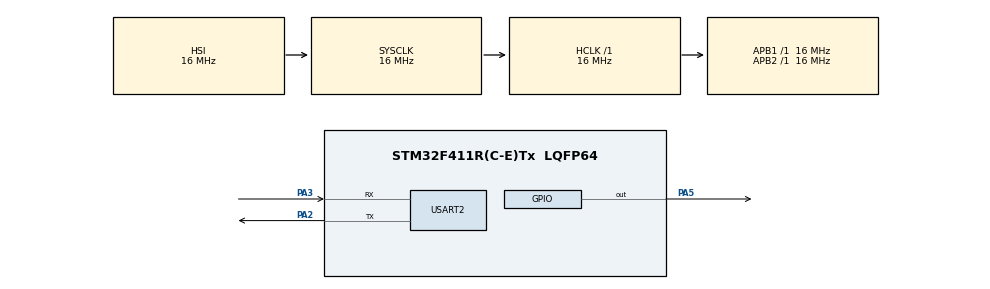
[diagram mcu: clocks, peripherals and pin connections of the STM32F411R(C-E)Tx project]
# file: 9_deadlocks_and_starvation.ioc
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FREERTOS.Tasks01=defaultTask,24,128,StartDefaultTask,Default,NULL,Dynamic,NULL,NULL
FREERTOS.configGENERATE_RUN_TIME_STATS=1
FREERTOS.configRECORD_STACK_HIGH_ADDRESS=1
FREERTOS.configUSE_NEWLIB_REENTRANT=1
FREERTOS.configUSE_STATS_FORMATTING_FUNCTIONS=1
Mcu.Family=STM32F4
Mcu.Name=STM32F411R(C-E)Tx
Mcu.Package=LQFP64
NVIC.PriorityGroup=NVIC_PRIORITYGROUP_4
NVIC.TIM1_TRG_COM_TIM11_IRQn=true\:15\:0\:false\:false\:true\:false\:false\:true\:true
NVIC.TimeBase=TIM1_TRG_COM_TIM11_IRQn
NVIC.TimeBaseIP=TIM11
PA2.Mode=Asynchronous
PA2.Signal=USART2_TX
PA3.Mode=Asynchronous
PA3.Signal=USART2_RX
PA5.Signal=GPIO_Output
PH0\ -\ OSC_IN.Mode=HSE-External-Oscillator
PH0\ -\ OSC_IN.Signal=RCC_OSC_IN
PH1\ -\ OSC_OUT.Mode=HSE-External-Oscillator
PH1\ -\ OSC_OUT.Signal=RCC_OSC_OUT
ProjectManager.HeapSize=0x200
ProjectManager.StackSize=0x400
ProjectManager.TargetToolchain=STM32CubeIDE
RCC.AHBFreq_Value=16000000
RCC.APB1Freq_Value=16000000
RCC.APB2Freq_Value=16000000
RCC.CortexFreq_Value=16000000
RCC.HSE_VALUE=25000000
RCC.HSI_VALUE=16000000
RCC.LSE_VALUE=32768
RCC.SYSCLKFreq_VALUE=16000000
RCC.VCOOutputFreq_Value=192000000
USART2.VirtualMode=VM_ASYNC
VP_FREERTOS_VS_CMSIS_V2.Mode=CMSIS_V2
VP_SYS_VS_tim11.Mode=TIM11
board=custom

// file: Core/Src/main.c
/* USER CODE BEGIN Header */
/**
 ******************************************************************************
 * @file           : main.c
 * @brief          : Main program body
 ******************************************************************************
 * @attention
 *
 * Copyright (c) 2026 STMicroelectronics.
 * All rights reserved.
 *
 * This software is licensed under terms that can be found in the LICENSE file
 * in the root directory of this software component.
 * If no LICENSE file comes with this software, it is provided AS-IS.
 *
 ******************************************************************************
 */
/* USER CODE END Header */
#include "main.h"
#include "cmsis_os.h"

/* USER CODE BEGIN Includes */

/* Standard library includes */
#include <stdio.h>
#include <stdlib.h>
#include <string.h>
#include <math.h>

/* FreeRTOS includes */
#include "timers.h"
#include "semphr.h"
#include "queue.h"

/* User includes */

/* USER CODE END Includes */

/* USER CODE BEGIN PD */
#define MAX(x, y) (((x) > (y)) ? (x) : (y))
#define MIN(x, y) (((x) < (y)) ? (x) : (y))

/* USER CODE END PD */

UART_HandleTypeDef huart2;

/* Definitions for defaultTask */
osThreadId_t defaultTaskHandle;
const osThreadAttr_t defaultTask_attributes = { .name = "defaultTask",
		.stack_size = 128 * 4, .priority = (osPriority_t) osPriorityNormal, };
/* USER CODE BEGIN PV */

/* ----------------------------- VARIABLES ---------------------------- */

//static const TickType_t task_delay = 20 / portTICK_PERIOD_MS;
/* Settings */
enum {
	NUM_TASKS = 5
};
// Number of tasks (philosophers)
enum {
	TASK_STACK_SIZE = 2048
};
// In bytes

// Globals
static char *task_names[NUM_TASKS];
static osThreadId_t *eatTaskHandles;
static osThreadAttr_t *eatTask_attributes;
/* flags */

/* Mutexes and Semaphores */
static SemaphoreHandle_t bin_sem; 		// Wait for parameters to be read
static SemaphoreHandle_t done_sem;  	// Notifies main task when done
static SemaphoreHandle_t chopstick[NUM_TASKS];

static SemaphoreHandle_t print_mutex;   // Serialize UART output

/* Queues and related structs */

/* ------------------------------ TASKS ------------------------------ */

osThreadId_t calcTaskHandle;
const osThreadAttr_t calcTask_attributes = { .name = "calcTask", .stack_size =
		512 * 4, .priority = (osPriority_t) osPriorityNormal, };

/* ----------------------------- CALLBACKS ---------------------------- */

/* USER CODE END PV */

void SystemClock_Config(void);
static void MX_GPIO_Init(void);
static void MX_USART2_UART_Init(void);
void StartDefaultTask(void *argument);

/* USER CODE BEGIN PFP */

/* ------------------------ FUNCTION SIGNATURES ----------------------- */

/* USER CODE END PFP */

int main(void) {

	/* MCU Configuration--------------------------------------------------------*/

	/* Reset of all peripherals, Initializes the Flash interface and the Systick. */
	HAL_Init();

	/* Configure the system clock */
	SystemClock_Config();

	/* Initialize all configured peripherals */
	MX_GPIO_Init();
	MX_USART2_UART_Init();
	/* USER CODE BEGIN 2 */

	/* Create Mutexes and Semaphores */

	/* Disable internal buffering for stdin */
	setvbuf(stdin, NULL, _IONBF, 0);

	/* USER CODE END 2 */

	/* Init scheduler */
	osKernelInitialize();

	/* Create the thread(s) */
	/* creation of defaultTask */
	defaultTaskHandle = osThreadNew(StartDefaultTask, NULL,
			&defaultTask_attributes);

	printf("[::::::::::::::: RTOS KERNEL START :::::::::::::::]\r\n");

	/* Start scheduler */
	osKernelStart();

	/* We should never get here as control is now taken by the scheduler */

	/* Infinite loop */
	while (1) {

	}
}

void SystemClock_Config(void) {
	RCC_OscInitTypeDef RCC_OscInitStruct = { 0 };
	RCC_ClkInitTypeDef RCC_ClkInitStruct = { 0 };

	/** Configure the main internal regulator output voltage
	 */
	__HAL_RCC_PWR_CLK_ENABLE();
	__HAL_PWR_VOLTAGESCALING_CONFIG(PWR_REGULATOR_VOLTAGE_SCALE1);

	/** Initializes the RCC Oscillators according to the specified parameters
	 * in the RCC_OscInitTypeDef structure.
	 */
	RCC_OscInitStruct.OscillatorType = RCC_OSCILLATORTYPE_HSI;
	RCC_OscInitStruct.HSIState = RCC_HSI_ON;
	RCC_OscInitStruct.HSICalibrationValue = RCC_HSICALIBRATION_DEFAULT;
	RCC_OscInitStruct.PLL.PLLState = RCC_PLL_NONE;
	if (HAL_RCC_OscConfig(&RCC_OscInitStruct) != HAL_OK) {
		Error_Handler();
	}

	/** Initializes the CPU, AHB and APB buses clocks
	 */
	RCC_ClkInitStruct.ClockType = RCC_CLOCKTYPE_HCLK | RCC_CLOCKTYPE_SYSCLK
			| RCC_CLOCKTYPE_PCLK1 | RCC_CLOCKTYPE_PCLK2;
	RCC_ClkInitStruct.SYSCLKSource = RCC_SYSCLKSOURCE_HSI;
	RCC_ClkInitStruct.AHBCLKDivider = RCC_SYSCLK_DIV1;
	RCC_ClkInitStruct.APB1CLKDivider = RCC_HCLK_DIV1;
	RCC_ClkInitStruct.APB2CLKDivider = RCC_HCLK_DIV1;

	if (HAL_RCC_ClockConfig(&RCC_ClkInitStruct, FLASH_LATENCY_0) != HAL_OK) {
		Error_Handler();
	}
}

static void MX_USART2_UART_Init(void) {

	huart2.Instance = USART2;
	huart2.Init.BaudRate = 115200;
	huart2.Init.WordLength = UART_WORDLENGTH_8B;
	huart2.Init.StopBits = UART_STOPBITS_1;
	huart2.Init.Parity = UART_PARITY_NONE;
	huart2.Init.Mode = UART_MODE_TX_RX;
	huart2.Init.HwFlowCtl = UART_HWCONTROL_NONE;
	huart2.Init.OverSampling = UART_OVERSAMPLING_16;
	if (HAL_UART_Init(&huart2) != HAL_OK) {
		Error_Handler();
	}

}

static void MX_GPIO_Init(void) {
	GPIO_InitTypeDef GPIO_InitStruct = { 0 };

	/* GPIO Ports Clock Enable */
	__HAL_RCC_GPIOH_CLK_ENABLE();
	__HAL_RCC_GPIOA_CLK_ENABLE();

	/*Configure GPIO pin Output Level */
	HAL_GPIO_WritePin(GPIOA, GPIO_PIN_5, GPIO_PIN_RESET);

	/*Configure GPIO pin : PA5 */
	GPIO_InitStruct.Pin = GPIO_PIN_5;
	GPIO_InitStruct.Mode = GPIO_MODE_OUTPUT_PP;
	GPIO_InitStruct.Pull = GPIO_NOPULL;
	GPIO_InitStruct.Speed = GPIO_SPEED_FREQ_LOW;
	HAL_GPIO_Init(GPIOA, &GPIO_InitStruct);

}

/* USER CODE BEGIN 4 */

/* ----------------------- FUNCTION DEFINITIONS ----------------------- */

/* printf redirection */
int __io_putchar(int ch) {
	HAL_UART_Transmit(&huart2, (uint8_t*) &ch, 1, HAL_MAX_DELAY);
	return ch;
}

/* scanf redirection */
int __io_getchar(void) {
	uint8_t ch = 0;

	/* Clear the Overrun flag before reading the first character */
	/* Only clear overrun flag if overrun actually occurred */
	if (__HAL_UART_GET_FLAG(&huart2, UART_FLAG_ORE)) {
		__HAL_UART_CLEAR_OREFLAG(&huart2);
	}

	HAL_UART_Receive(&huart2, (uint8_t*) &ch, 1, HAL_MAX_DELAY);

	if (ch == '\r')
		ch = '\n';  // Convert CR to LF so gets() terminates

	HAL_UART_Transmit(&huart2, (uint8_t*) &ch, 1, HAL_MAX_DELAY);
	return ch;
}

/* ------------------- FUNCTION DEFINITIONS (TASKS) ------------------- */

void eat(void *parameters) {

	uint8_t phil_num;
	uint8_t chopA_num;
	uint8_t chopB_num;

	// Copy parameter and increment semaphore count
	phil_num = *(int*) parameters;
	xSemaphoreGive(bin_sem);

	// Lets consider the chopstick index as its ID
	chopA_num = phil_num;
	chopB_num = (phil_num + 1) % NUM_TASKS;

	// Take chopstick with lower ID
	xSemaphoreTake(chopstick[MIN(chopA_num, chopB_num)], portMAX_DELAY);
	xSemaphoreTake(print_mutex, portMAX_DELAY);
	printf("Philosopher %i took chopstick %i\r\n", phil_num, phil_num);
    xSemaphoreGive(print_mutex);

	// Add some delay to force deadlock
	vTaskDelay(1 / portTICK_PERIOD_MS);

	// Take chopstick with higher ID
	xSemaphoreTake(chopstick[MAX(chopA_num, chopB_num)], portMAX_DELAY);
	xSemaphoreTake(print_mutex, portMAX_DELAY);
	printf("Philosopher %i took chopstick %i\r\n", phil_num, (phil_num + 1) % NUM_TASKS);
    xSemaphoreGive(print_mutex);

	// Do some eating
	xSemaphoreTake(print_mutex, portMAX_DELAY);
    xSemaphoreGive(print_mutex);
	printf("Philosopher %i is eating\r\n", phil_num);
	vTaskDelay(10 / portTICK_PERIOD_MS);

	/* Its good practice to give in the reverse order of taking semaphores and mutexes */

	// Put down chopstick with higher ID
	xSemaphoreGive(chopstick[MAX(chopA_num, chopB_num)]);
	xSemaphoreTake(print_mutex, portMAX_DELAY);
	printf("Philosopher %i returned chopstick %i\r\n", phil_num,
			(phil_num + 1) % NUM_TASKS);
    xSemaphoreGive(print_mutex);

	// Put down chopstick with lower ID
	xSemaphoreGive(chopstick[MIN(chopA_num, chopB_num)]);
	xSemaphoreTake(print_mutex, portMAX_DELAY);
	printf("Philosopher %i returned chopstick %i\r\n", phil_num, phil_num);
    xSemaphoreGive(print_mutex);

	// Notify main task and delete self
	xSemaphoreGive(done_sem);
	vTaskDelete(NULL);
}

/* USER CODE END 4 */

void StartDefaultTask(void *argument) {
	/* USER CODE BEGIN 5 */

	eatTaskHandles = pvPortMalloc(NUM_TASKS * sizeof(osThreadId_t));
	eatTask_attributes = pvPortMalloc(NUM_TASKS * sizeof(osThreadAttr_t));

	// Create kernel objects before starting tasks
	print_mutex = xSemaphoreCreateMutex();
	bin_sem = xSemaphoreCreateBinary();
	done_sem = xSemaphoreCreateCounting(NUM_TASKS, 0);
	for (int i = 0; i < NUM_TASKS; i++) {
		chopstick[i] = xSemaphoreCreateMutex();
	}

	vTaskDelay(1000 / portTICK_PERIOD_MS);

	// Have the philosphers start eating
	for (int i = 0; i < NUM_TASKS; i++) {

		task_names[i] = pvPortMalloc(sizeof(char) * 20);
		sprintf(task_names[i], "Philosopher %i", i);

		eatTask_attributes[i] = (osThreadAttr_t ) { .name = task_names[i],
						.stack_size = TASK_STACK_SIZE, .priority =
								(osPriority_t) osPriorityNormal, };

		eatTaskHandles[i] = osThreadNew(eat, (void*) &i,
				&(eatTask_attributes[i]));

		xSemaphoreTake(bin_sem, portMAX_DELAY);
	}

	// Wait until all the philosophers are done
	for (int i = 0; i < NUM_TASKS; i++) {
		xSemaphoreTake(done_sem, portMAX_DELAY);
	}

	// Say that we made it through without deadlock
	xSemaphoreTake(print_mutex, portMAX_DELAY);
	printf("Done! No deadlock occurred!\r\n");
    xSemaphoreGive(print_mutex);

	vTaskDelete(NULL);
	/* USER CODE END 5 */
}

void HAL_TIM_PeriodElapsedCallback(TIM_HandleTypeDef *htim) {
	/* USER CODE BEGIN Callback 0 */
//	if (htim->Instance == TIM3) {
//
//	}
	/* USER CODE END Callback 0 */
	if (htim->Instance == TIM11) {
		HAL_IncTick();
	}
}

void Error_Handler(void) {
	__disable_irq();
	while (1) {
	}
}
